AUTOSAR XML (schema 4-0-3)
package /ComponentTypes
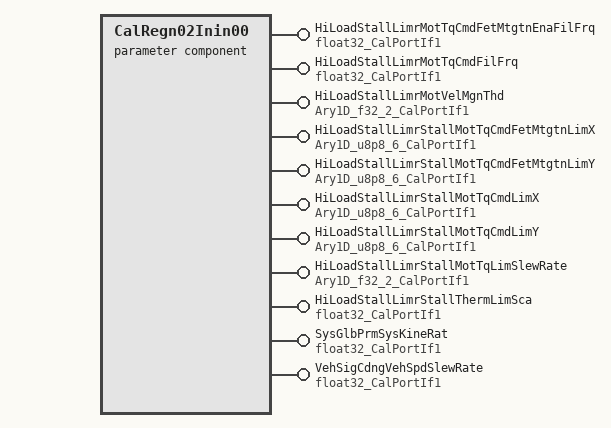
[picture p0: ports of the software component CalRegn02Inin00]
  parameter sw component type CalRegn02Inin00
    11 x provide port:
      HiLoadStallLimrMotTqCmdFetMtgtnEnaFilFrq: parameter-provide-com-spec{init-value=2, parameter=Val}, provided-interface=float32_CalPortIf1
      HiLoadStallLimrMotTqCmdFilFrq: parameter-provide-com-spec{init-value=2, parameter=Val}, provided-interface=float32_CalPortIf1
      HiLoadStallLimrMotVelMgnThd: parameter-provide-com-spec{init-value=[1.375, 1.375], parameter=Ary1D}, provided-interface=Ary1D_f32_2_CalPortIf1
      HiLoadStallLimrStallMotTqCmdFetMtgtnLimX: parameter-provide-com-spec{init-value=[0, 563, 640, 717, 768, 768], parameter=Ary1D}, provided-interface=Ary1D_u8p8_6_CalPortIf1
      HiLoadStallLimrStallMotTqCmdFetMtgtnLimY: parameter-provide-com-spec{init-value=[768, 768, 512, 256, 0, 0], parameter=Ary1D}, provided-interface=Ary1D_u8p8_6_CalPortIf1
      HiLoadStallLimrStallMotTqCmdLimX: parameter-provide-com-spec{init-value=[0, 563, 640, 717, 768, 768], parameter=Ary1D}, provided-interface=Ary1D_u8p8_6_CalPortIf1
      HiLoadStallLimrStallMotTqCmdLimY: parameter-provide-com-spec{init-value=[768, 768, 512, 256, 0, 0], parameter=Ary1D}, provided-interface=Ary1D_u8p8_6_CalPortIf1
      HiLoadStallLimrStallMotTqLimSlewRate: parameter-provide-com-spec{init-value=[0.101563, 0.101563], parameter=Ary1D}, provided-interface=Ary1D_f32_2_CalPortIf1
      HiLoadStallLimrStallThermLimSca: parameter-provide-com-spec{init-value=0.5, parameter=Val}, provided-interface=float32_CalPortIf1
      SysGlbPrmSysKineRat: parameter-provide-com-spec{init-value=22, parameter=Val}, provided-interface=float32_CalPortIf1
      VehSigCdngVehSpdSlewRate: parameter-provide-com-spec{init-value=50, parameter=Val}, provided-interface=float32_CalPortIf1
